# ESP32C6_RADIO register map
File version: 0.1.0
Registers are 32-bit, read-write, no defined reset value unless marked. A register's access mark holds for its fields unless they carry their own. Offsets are from the block's base; [hi:lo] are bit positions; {n}, {i} and the like mark numbered series.

## DUMP — Dump and DAC engine Same RUN, TRIGGER, DONE and COUNT bits as the S3 at another address (*upstream* `modules/lib/esp-sdr/main/families/c5_c6_c61/receiver.c`, `modules/lib/esp-sdr/main/targets/esp32c6/chip.h`). Receive runs at 80 MS/s only; the transmit side is a DAC engine at 0x600a900c (DUMP_DAC_TRIG_REG, below), which no vendor code programs: the C6 `dactrig()` only writes a ramp into 0x40840000 (*decompile* C6 `librftest.a` `mac_common.o`). Base 0x600a9000 has no name in the HAL. Each capture and each playback needs the clocks in MODEM_SYSCON forced on and an SRAM block handed to the engine in HP_SYSTEM_SRAM_USAGE_CONF_REG. **Receive rate.** The C6 `adctrig()` starts only mode 0 by software; the other modes wait for a hardware event. It writes no part of DUMP_MODE_REG (0x600a9008) but the source field, DUMP_SRC, and never reads the argument that the C5 and C61 versions turn into a rate (*decompile* C6 `librftest.a` `mac_common.o`): | `adctrig()` mode | DUMP_SRC | Also | |---|---|---| | 0 | 15 | software start | | 1, 3 | 1 | | | 2 | 0 | | | 4 | 2 | | | 5 | 3 | tries to send a frame each poll, at most one per `tx_frame_delay_us` (800 by default) | | 6 | 4 | as mode 5 | | 7 | 5 | Wi-Fi MAC event selector WIFIMAC_EVENT_SEL_REG (0x600a4e30): bit 8 set, bits 7:0 the event | | 8 | 0 | BTBB_DUMP_GATE (0x600a20b4 bit 0) set, lanes 0x0e to 0x11, BLE receiver started | Upstream found no other source that gives a uniform stream, and neither `adc_rate_set()` nor candidate divider bits changed the timing (*upstream* `git show 34bb79b:docs/rx-controls.md`, "C6 sample-rate investigation"). Upstream's C6 ring is gapless at 80 MS/s, rotating SRAM blocks 1 and 2 under a circular DUMP_CTRL_REG (DUMP_CIRCULAR, bit 17, count 16384), and consumes it as FFT windows (*upstream* `modules/lib/esp-sdr/main/common/ring_capture.c:96-131, 1485-1507`): the 160 MHz CPU has 2 cycles per sample, too few to decimate the whole stream. Leads for a continuous C6 receive below 80 MS/s (the first one probed): - The modem diagnostic bus into PARL_IO. A third-party project, not re-checked here, reports for the ESP32-C5 that the dump's I/Q MSBs appear on MODEM_DIAG (Q[9:6] on lines 9:6, I[9:6] on 19:16), and that routed through the GPIO matrix into PARL_IO, a cyclic 40 MS/s capture takes every second sample of the 80 MS/s bus as 4+4-bit I/Q, bit-perfect in a bounded capture (it claims no gapless running across ring wraps; [Twotoz/C5VRX](https://github.com/Twotoz/C5VRX/blob/a165e19db47ebd49051217d7c968a1b8220c20fb/docs/continuous-iq-findings.md)). The C6 selector registers are DUMP_DIAG_SEL0_REG and DUMP_DIAG_SEL1_REG (0x600a9018 and 0x600a901c), and the diag lines are enabled in IO_MUX_MODEM_DIAG_EN_REG (0x600900bc); both below. Which selector value puts receive I/Q on the C6 bus is unknown. Sampling below 80 MHz decimates without filtering, so the analog low-pass has to be narrowed first. Probed 2026-10-19 (`tmp/scratch/c6diag`, not in the tree: the dump engine set up by a burst capture and left running circular, all lines enabled, two lanes at a time looped back through GPIO5 and GPIO11 and read by the CPU at some 20 MHz; GPIO5 is MTDI and needs its pad function set to GPIO first). With a strong tone, selector values sel0 = 4n (sel1 = 0) drive lanes 16 to 22 and 26 to 29; their toggle rates fall from lane 16 (some 350 per 4096 reads) to lane 22 (some 30, the sign rate of the 100 kHz tone), like the bits of a sampled value rather than copies of a sign (an earlier sweep read them as sign-like). Odd values 3 + 4n drive lane 19 only. The bit mapping is not resolved: two pads see only a pair at a time. A parallel capture needs a free pad per lane, which the WHY2025 badge's C6 does not have (its SDIO link takes GPIO18 to 23), and a XIAO ESP32C6 has the pads but only USB-Serial-JTAG to send the samples on. - The 802.11p clock mode: `phy_11p_set(1, m)` writes MODEM_SYSCON_WIFI_BB_CFG_REG (0x600a981c) bits 4:2 = 4 for m = 0, else 5, presumably for 10 and 5 MHz channels, and clears AGC_R30_REG (0x600a7030) bit 5 (*decompile* C6 `libphy.a` `phy_feature.o`). Whether the dump follows the slower clock is unknown. - The BLE dump (mode 8 above): rate unknown; it runs only while the BLE receiver does.
Base 0x600A9000
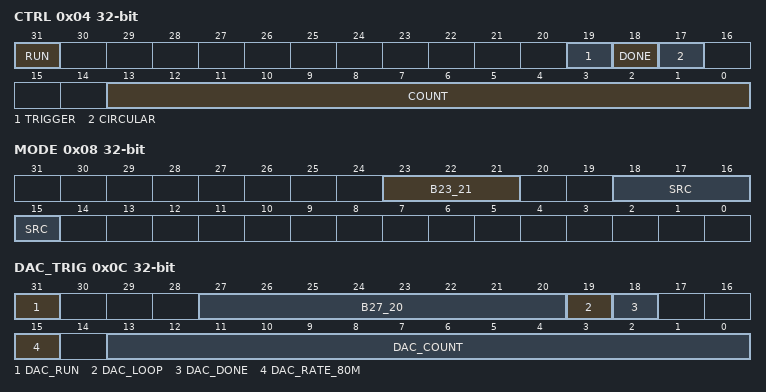
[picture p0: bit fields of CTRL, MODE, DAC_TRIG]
0x04 CTRL — Receive side: run, trigger and count of a capture No rate field, unlike the S3's: receive runs at 80 MS/s only. Evidence: *working* `lib/esp_sdr/src/esp_sdr_priv.h:78-82`, `lib/esp_sdr/src/esp_sdr_rx.c:302-310`; *upstream* `modules/lib/esp-sdr/main/targets/esp32c6/chip.h:43-46` (DUMP_RUN, DUMP_TRIGGER, DUMP_DONE, DUMP_COUNT)
  [31] RUN — Enables the engine, as on the S3.
  [19] TRIGGER wo — As on the S3, write 1, then 0, to start a one-shot capture.
  [18] DONE — As on the S3, reads 1 once DUMP_COUNT words are written. Write DUMP_COUNT with DUMP_DONE first to clear a stale DUMP_DONE, as the stock sequence does.
  [17] CIRCULAR — Circular ring: set with DUMP_RUN and bit 14 (upstream's 0x24000), the engine writes the owned block's first 16384 words over and over at 80 MS/s (205 us a lap) until DUMP_RUN is cleared. The ring stays 16384 words whatever DUMP_COUNT holds (16384, 32768 and 0 alike), so the block's upper 64 KiB is never written; the CPUs cannot read the ring while it runs (see "SRAM bank ownership"). The library's triggered snapshots use it. Evidence: *measured* bench 2026-10-19 (sentinel fill, ring size and index); *working* `lib/esp_sdr/src/esp_sdr_trig.c`; *upstream* `modules/lib/esp-sdr/main/common/ring_capture.c:104, 1499-1505`
  [13:0] COUNT — Words to capture, 256 to 16380; 16380 samples take about 205 us.
0x08 MODE — Dump source; the live write index in upstream's ring While DUMP_CIRCULAR runs, bits 14:0 are the write index: bits 13:0 the word the engine writes next, one step per sample (80 MS/s), and bit 14 toggling every lap. They read 0 once DUMP_RUN is cleared, so a stopped ring's position has to be read just before the stop. Evidence: *measured* bench 2026-10-19; *working* `lib/esp_sdr/src/esp_sdr_trig.c`; *upstream* `modules/lib/esp-sdr/main/common/ring_capture.c:96, 1507` (write index)
  [23:21] B23_21 ro — Not a rate field, unlike on the C5 and C61, where these bits take a rate code: written bits do not stay, and captures and replays keep their timing. Evidence: *measured* bench 2026-10-11; C5 and C61: *upstream* `modules/lib/esp-sdr/main/targets/esp32c5/chip.h:11`, `modules/lib/esp-sdr/main/targets/esp32c61/chip.h:20-21`
  [18:15] SRC — Dump source; 15 = raw receive I/Q, as the stock `adctrig()` (see "Receive rate" above for the other sources). The library writes 15. Evidence: *working* `lib/esp_sdr/src/esp_sdr_priv.h:83-85`; *upstream* `modules/lib/esp-sdr/main/targets/esp32c6/chip.h:6, 39`
0x0C DAC_TRIG — Transmit side: run, loop, rate and count of a playback 8 bytes above DUMP_CTRL_REG, as on the S3. Bits 14, 16 and 17 do not read back. - One word per sample, I in bits 9:0 and Q in 19:10, as for the S3's DAC (see "Sample word formats"): a complex tone of k cycles in n words plays at +k/n of the rate (200 cycles in 16000 words: 0.5 MHz at 40 MS/s, 1 MHz at 80 MS/s), its image 37 to 40 dB down. All-zero words play nothing, a constant word a carrier. - What playback needs: the dump clocks forced on as for a capture (without them DUMP_DAC_DONE still sets on time but nothing reaches the antenna; see MODEM_SYSCON_CLK_CONF_REG), SRAM block 2 handed to the engine (HP_SYSTEM_SRAM_USAGE = 4, that is 0x60095004 bits 11:8, samples from 0x40840000), and the transmit chain on without its tone: the vendor CW (`esp_phy_wifi_tx_tone(1, 6, 80)`), then bit 18 (FE_TONE_EN) of 0x600a0420 and 0x600a0424 cleared. That leaves the DAC source select, FE_DAC_SRC (0x600a0414 bits 1:0), at 0, the tone generator's setting (see "Front end"). - While the engine owns the block, CPU stores are dropped and loads return other data, as during a capture. No vendor blob or ROM of the C6, C5 or C61 writes this register. Only upstream code does: the C5 transmitter of its first upload (`emit_dma()`, removed in ab76232), and the C61 capture and ring code, which writes 0 to it before each capture. Upstream's S31 code clears bit 31 of its counterpart, 0x2010900c, when it sets up the dump. Evidence: *measured* bench 2026-10-11 (read-back, sample format, what playback needs, CPU access) Evidence: *decompile* (no vendor or ROM writer) Evidence: `git show e605684:main/c5_main.c`, `emit_dma()` (C5 transmitter) Evidence: *upstream* `modules/lib/esp-sdr/main/targets/esp32c61/chip.h:12, 17`, `modules/lib/esp-sdr/main/common/ring_capture.c:1493` (C61) Evidence: *upstream* `modules/lib/esp-sdr/main/targets/esp32s31/burst/receiver.c:37, 123` (S31)
  [31] DAC_RUN — Written with DUMP_DAC_COUNT and with DUMP_DAC_LOOP clear: one pass, with no trigger pulse as on the S3. Evidence: *measured* bench 2026-10-11
  [27:20] B27_20 — Read back as written; effect untested. The S3 `dactrig()` writes the count's low byte here (see the ESP32-S3 page); upstream's C5 replay uses it as a repeat count, 0 meaning endless with bit 19 set. Evidence: *measured* bench 2026-10-11 (read-back only); *upstream* `git show e605684:main/c5_main.c`, comment above `emit_dma()`
  [19] DAC_LOOP — Set with DUMP_DAC_RUN (DUMP_B27_20 at 0): the engine replays the first DUMP_DAC_COUNT words back to back until DUMP_DAC_RUN is cleared; DUMP_DAC_DONE stays clear. Evidence: *measured* bench 2026-10-11
  [18] DAC_DONE ro — Sets after one pass. Evidence: *measured* bench 2026-10-11
  [15] DAC_RATE_80M — 1 = 80 MS/s, 0 = 40 MS/s: a pass takes 4 cycles of the 160 MHz CPU per word at 40 MS/s (DUMP_DAC_COUNT 1000 to 16000), 2 at 80 MS/s (DUMP_DAC_COUNT 16000). The rate is this bit, as on the S3, not bit 17 as in upstream's C5 replay. Evidence: *measured* bench 2026-10-11
  [13:0] DAC_COUNT — Words to play from the start of the owned block, up to 16383. Evidence: *measured* bench 2026-10-11
0x14 CONFIG — Lane selectors: the sources packed into a dump word
  [24:0] LANES — Lane selectors as the S3's DUMP_CONFIG_REG (0x60033d90, see the ESP32-S3 page): four 6-bit lane selectors, lane n in bits 6n+5:6n. The library clears the field, then sets it to 0x000c2040. `adctrig()` mode 8, the BLE dump, uses lanes 0x0e to 0x11 (see "Receive rate" above). Evidence: *working* `lib/esp_sdr/src/esp_sdr_rx.c:258`; *upstream* `modules/lib/esp-sdr/main/targets/esp32c6/chip.h:38` Evidence: *decompile* C6 `librftest.a` `mac_common.o` (mode 8)
{0x18+4i} DIAG_SEL{i} (i=0..1) — Modem diagnostic bus selectors `gpio_diag_init_ble()` writes 1 to DUMP_DIAG_SEL0_REG and `coex_hw_debug_matrix_config()` 2 to DUMP_DIAG_SEL1_REG, on the C6 as on the C5, which has the pair at 0x600a9404 and 0x600a9408. On the C6 each function then enables diag lines in IO_MUX_MODEM_DIAG_EN_REG: 0xffff0000 and 0x0000000f. Which selector value puts receive I/Q on the C6 bus is unknown (see the leads above). Evidence: *decompile* C6 and C5 `libble_app.a` `gpio_diag.c.o`, `libcoexist.a` `coexist_hw.o`
